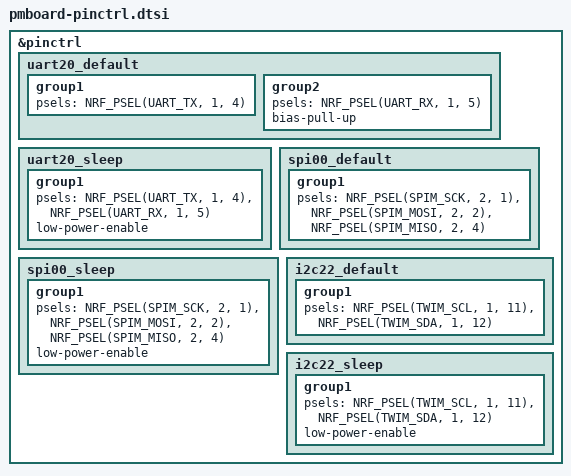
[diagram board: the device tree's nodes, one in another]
/*
 * Pin map of the crank pod board: docs/02-hardware.md, "Pinos do módulo",
 * and hardware_powermeter/09-modulo-de-radio.md.
 *
 * Every bus pin below is the one NORDIC uses for that peripheral on this
 * SoC, and that is not deference - it is the only evidence available. A
 * TWIM's SCL and a SPIM's SCK need a clock-capable pin, the nRF54L15's
 * table of them is not in this repository, and Nordic's own board files
 * are. Where each was read:
 *
 *   spi00  SCK P2.01, MOSI P2.02, MISO P2.04
 *          zephyr/boards/nordic/nrf54l15dk/
 *              nrf54l15dk_nrf54l_05_10_15-pinctrl.dtsi
 *   i2c22  SCL P1.11, SDA P1.12
 *          nrf/boards/shields/pca63565/boards/
 *              nrf54l15dk_nrf54l15_cpuapp.overlay
 *   uart20 TX P1.04, RX P1.05
 *          the same DK pinctrl
 *
 * The serial blocks follow the ports: spi00 is on P2, and blocks 20, 21 and
 * 22 are on P1. Blocks 20/21/22 are the SAME peripheral at three addresses -
 * each one serves as i2c, spi OR uart, one at a time - so uart20 and i2c22
 * can coexist and uart22 could not.
 *
 * Every pin below is a pad of the HOLYIOT-26001-A, as the table of
 * 09-modulo-de-radio.md lists them: P2.01 is pad 10, P2.02 pad 30, P2.04
 * pad 16, P1.11 pad 34, P1.12 pad 33, P1.04 pad 18 and P1.05 pad 17.
 */

&pinctrl {
	/* ---- Console, commands and MCUboot recovery, out through the connector ---- */
	uart20_default: uart20_default {
		group1 {
			psels = <NRF_PSEL(UART_TX, 1, 4)>;
		};

		group2 {
			psels = <NRF_PSEL(UART_RX, 1, 5)>;
			bias-pull-up;
		};
	};

	uart20_sleep: uart20_sleep {
		group1 {
			psels = <NRF_PSEL(UART_TX, 1, 4)>,
				<NRF_PSEL(UART_RX, 1, 5)>;
			low-power-enable;
		};
	};

	/* ---- Bridge converter and accelerometer: spi00, the fast SPI of port P2 ---- */
	spi00_default: spi00_default {
		group1 {
			psels = <NRF_PSEL(SPIM_SCK, 2, 1)>,
				<NRF_PSEL(SPIM_MOSI, 2, 2)>,
				<NRF_PSEL(SPIM_MISO, 2, 4)>;
		};
	};

	spi00_sleep: spi00_sleep {
		group1 {
			psels = <NRF_PSEL(SPIM_SCK, 2, 1)>,
				<NRF_PSEL(SPIM_MOSI, 2, 2)>,
				<NRF_PSEL(SPIM_MISO, 2, 4)>;
			low-power-enable;
		};
	};

	/* ---- The bridge's thermometer and the fuel gauge: i2c22 on port P1 ---- */
	i2c22_default: i2c22_default {
		group1 {
			psels = <NRF_PSEL(TWIM_SCL, 1, 11)>,
				<NRF_PSEL(TWIM_SDA, 1, 12)>;
		};
	};

	i2c22_sleep: i2c22_sleep {
		group1 {
			psels = <NRF_PSEL(TWIM_SCL, 1, 11)>,
				<NRF_PSEL(TWIM_SDA, 1, 12)>;
			low-power-enable;
		};
	};
};
